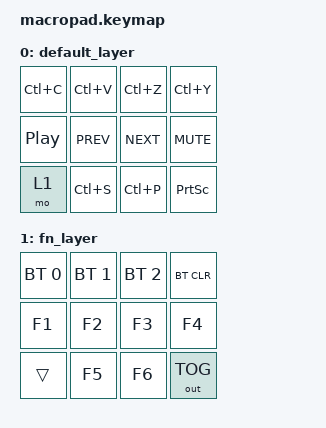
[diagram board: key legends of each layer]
#include <behaviors.dtsi>
#include <dt-bindings/zmk/keys.h>
#include <dt-bindings/zmk/bt.h>
#include <dt-bindings/zmk/outputs.h>

/ {
    keymap {
        compatible = "zmk,keymap";

        default_layer {
            bindings = 
                &kp LC(C)  &kp LC(V)  &kp LC(Z)  &kp LC(Y)
                &kp C_PP   &kp C_PREV &kp C_NEXT &kp C_MUTE
                &mo 1      &kp LC(S)  &kp LC(P)  &kp PSCRN
            >;
        };

        fn_layer {
            bindings = 
                &bt BT_SEL 0 &bt BT_SEL 1 &bt BT_SEL 2 &bt BT_CLR
                &kp F1       &kp F2       &kp F3       &kp F4
                &trans       &kp F5       &kp F6       &out OUT_TOG
            >;
        };
    };
};
